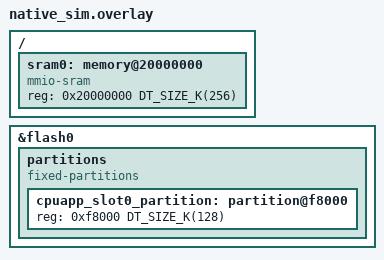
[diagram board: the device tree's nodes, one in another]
/*
 * Copyright (c) 2025 Nordic Semiconductor ASA
 *
 * SPDX-License-Identifier: LicenseRef-Nordic-5-Clause
 */

&flash0 {
	partitions {
		compatible = "fixed-partitions";
		#address-cells = <1>;
		#size-cells = <1>;

		/* Use the last 128KB of NVM as image storage partition. */
		cpuapp_slot0_partition: partition@f8000 {
			reg = <0xf8000 DT_SIZE_K(128)>;
		};
	};
};

/ {
	sram0: memory@20000000 {
		compatible = "mmio-sram";
		reg = <0x20000000 DT_SIZE_K(256)>;
	};
};
